# DMAC1 register map
Registers from a debugger description file.
Registers are 64-bit, access not given, no defined reset value unless marked. A register's access mark holds for its fields unless they carry their own. Addresses are absolute; registers are grouped by the start of their names; lines under a group give offsets from that group; [hi:lo] are bit positions; {n}, {i} and the like mark numbered series; 'fields as' and 'values as' point back to an identical list; <NAME> marks a mode.

## DMAC1
{0x40104000+0x58*i} DMAC1/SAR{i} (i=0..7)
  [31:0] SAR
{0x40104008+0x58*i} DMAC1/DAR{i} (i=0..7)
  [31:0] DAR
{0x40104010+0x58*i} DMAC1/LLP{i} (i=0..7)
  [31:2] LOC
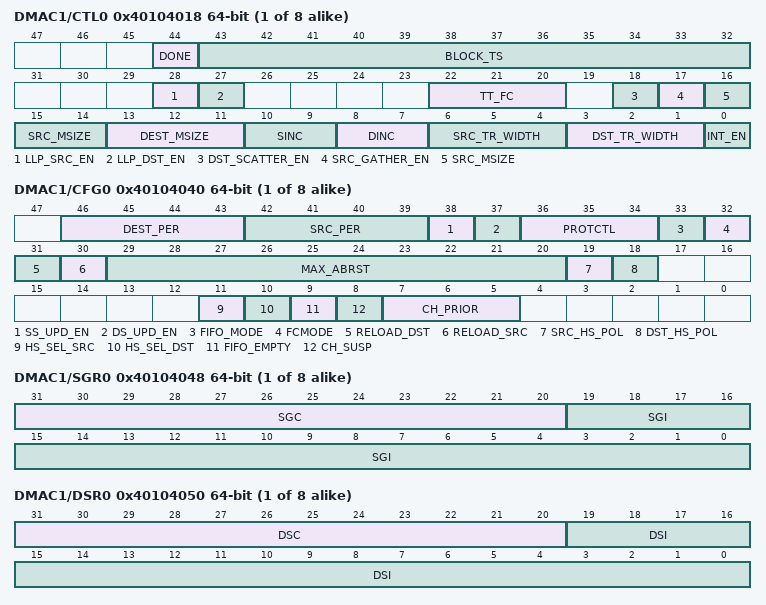
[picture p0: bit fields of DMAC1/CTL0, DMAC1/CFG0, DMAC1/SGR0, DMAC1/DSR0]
{0x40104018+0x58*i} DMAC1/CTL{i} (i=0..7)
  [44] DONE, [43:32] BLOCK_TS, [28] LLP_SRC_EN, [27] LLP_DST_EN, [22:20] TT_FC, [18] DST_SCATTER_EN, [17] SRC_GATHER_EN, [16:14] SRC_MSIZE, [13:11] DEST_MSIZE, [10:9] SINC, [8:7] DINC, [6:4] SRC_TR_WIDTH, [3:1] DST_TR_WIDTH, [0] INT_EN
{0x40104020+0x58*i} DMAC1/SSTAT{i} (i=0..7)
  [31:0] SSTAT
{0x40104028+0x58*i} DMAC1/DSTAT{i} (i=0..7)
  [31:0] DSTAT
{0x40104030+0x58*i} DMAC1/SSTATAR{i} (i=0..7)
  [31:0] SSTATAR
{0x40104038+0x58*i} DMAC1/DSTATAR{i} (i=0..7)
  [31:0] DSTATAR
{0x40104040+0x58*i} DMAC1/CFG{i} (i=0..7)
  [46:43] DEST_PER, [42:39] SRC_PER, [38] SS_UPD_EN, [37] DS_UPD_EN, [36:34] PROTCTL, [33] FIFO_MODE, [32] FCMODE, [31] RELOAD_DST, [30] RELOAD_SRC, [29:20] MAX_ABRST, [19] SRC_HS_POL, [18] DST_HS_POL, [11] HS_SEL_SRC, [10] HS_SEL_DST, [9] FIFO_EMPTY, [8] CH_SUSP, [7:5] CH_PRIOR
{0x40104048+0x58*i} DMAC1/SGR{i} (i=0..7)
  [31:20] SGC, [19:0] SGI
{0x40104050+0x58*i} DMAC1/DSR{i} (i=0..7)
  [31:20] DSC, [19:0] DSI
0x401042C0 DMAC1/RawTfr
  [7:0] RAW
0x401042C8 DMAC1/RawBlock
  [7:0] RAW
0x401042D0 DMAC1/RawSrcTran
  [7:0] RAW
0x401042D8 DMAC1/RawDstTran
  [7:0] RAW
0x401042E0 DMAC1/RawErr
  [7:0] RAW
0x401042E8 DMAC1/StatusTfr ro
  [7:0] STATUS
0x401042F0 DMAC1/StatusBlock ro
  [7:0] STATUS
0x401042F8 DMAC1/StatusSrcTran ro
  [7:0] STATUS
0x40104300 DMAC1/StatusDstTran ro
  [7:0] STATUS
0x40104308 DMAC1/StatusErr ro
  [7:0] STATUS
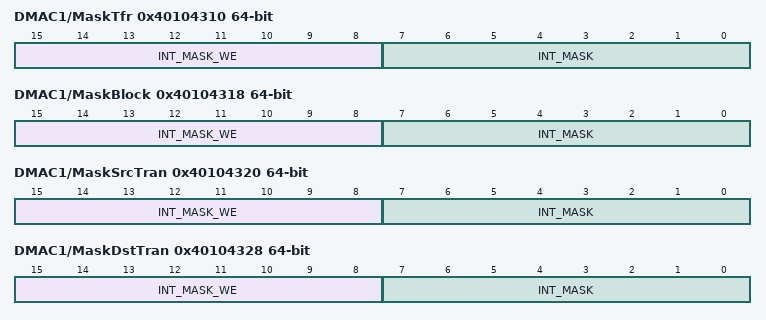
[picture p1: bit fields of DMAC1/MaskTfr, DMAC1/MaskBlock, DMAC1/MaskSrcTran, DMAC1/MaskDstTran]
0x40104310 DMAC1/MaskTfr
  [15:8] INT_MASK_WE, [7:0] INT_MASK
0x40104318 DMAC1/MaskBlock
  [15:8] INT_MASK_WE, [7:0] INT_MASK
0x40104320 DMAC1/MaskSrcTran
  [15:8] INT_MASK_WE, [7:0] INT_MASK
0x40104328 DMAC1/MaskDstTran
  [15:8] INT_MASK_WE, [7:0] INT_MASK
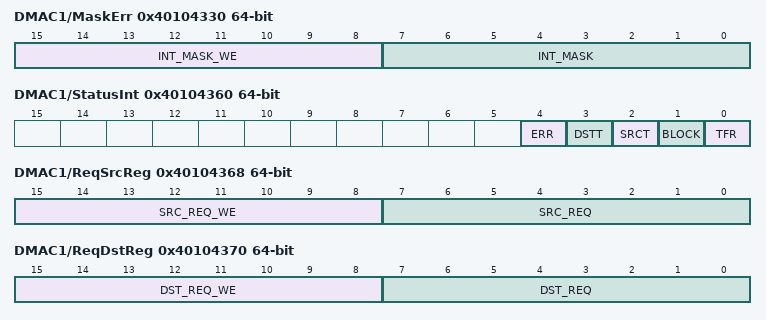
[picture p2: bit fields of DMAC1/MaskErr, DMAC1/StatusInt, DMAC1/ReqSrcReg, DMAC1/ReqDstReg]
0x40104330 DMAC1/MaskErr
  [15:8] INT_MASK_WE, [7:0] INT_MASK
0x40104338 DMAC1/ClearTfr wo
  [7:0] CLEAR
0x40104340 DMAC1/ClearBlock wo
  [7:0] CLEAR
0x40104348 DMAC1/ClearSrcTran wo
  [7:0] CLEAR
0x40104350 DMAC1/ClearDstTran wo
  [7:0] CLEAR
0x40104358 DMAC1/ClearErr wo
  [7:0] CLEAR
0x40104360 DMAC1/StatusInt ro
  [4] ERR, [3] DSTT, [2] SRCT, [1] BLOCK, [0] TFR
0x40104368 DMAC1/ReqSrcReg
  [15:8] SRC_REQ_WE, [7:0] SRC_REQ
0x40104370 DMAC1/ReqDstReg
  [15:8] DST_REQ_WE, [7:0] DST_REQ
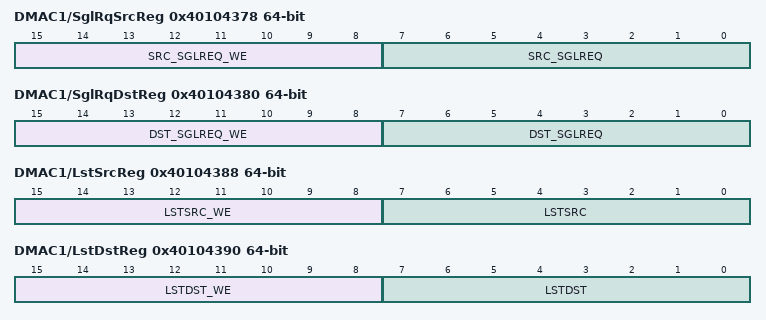
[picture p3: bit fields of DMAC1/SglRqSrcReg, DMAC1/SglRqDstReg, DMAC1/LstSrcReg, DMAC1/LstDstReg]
0x40104378 DMAC1/SglRqSrcReg
  [15:8] SRC_SGLREQ_WE, [7:0] SRC_SGLREQ
0x40104380 DMAC1/SglRqDstReg
  [15:8] DST_SGLREQ_WE, [7:0] DST_SGLREQ
0x40104388 DMAC1/LstSrcReg
  [15:8] LSTSRC_WE, [7:0] LSTSRC
0x40104390 DMAC1/LstDstReg
  [15:8] LSTDST_WE, [7:0] LSTDST
0x40104398 DMAC1/DmaCfgReg
  [0] DMA_EN
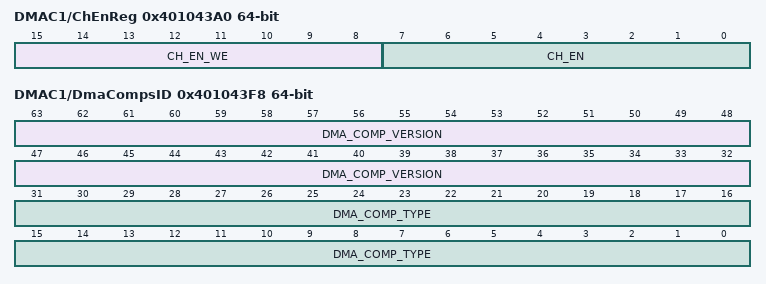
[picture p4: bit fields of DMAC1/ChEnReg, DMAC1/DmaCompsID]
0x401043A0 DMAC1/ChEnReg
  [15:8] CH_EN_WE, [7:0] CH_EN
0x401043A8 DMAC1/DmaIdReg ro
  [31:0] DMA_ID
0x401043B0 DMAC1/DmaTestReg
  [0] TEST_SLV_IF
0x401043F8 DMAC1/DmaCompsID ro
  [63:32] DMA_COMP_VERSION, [31:0] DMA_COMP_TYPE
